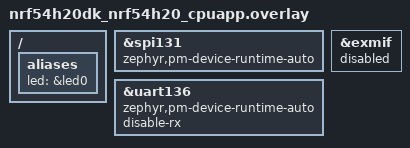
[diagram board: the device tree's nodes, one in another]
/ {
	aliases {
		led = &led0;
		/delete-property/ led1;
	};
};

/delete-node/ &led1;

dut_spi: &spi131 {
	zephyr,pm-device-runtime-auto;
};

&exmif {
	status = "disabled";
};

&uart136 {
	zephyr,pm-device-runtime-auto;
	disable-rx;
};
